# R7FA2L1AB register map
Vendor: Renesas Electronics Corporation; Series: RA2L1; File version: 1.60.00
CPU: CM23 r1p0, little endian, MPU, no FPU, VTOR, 2 interrupt priority bits, 32 interrupts
Registers are 8-bit, read-write, reset 0x0 unless marked. A register's access mark holds for its fields unless they carry their own. Offsets are from the block's base; [hi:lo] are bit positions; {n}, {i} and the like mark numbered series; 'fields as' and 'values as' point back to an identical list.

## PFS — Pmn Pin Function Control Register
Base 0x40040800
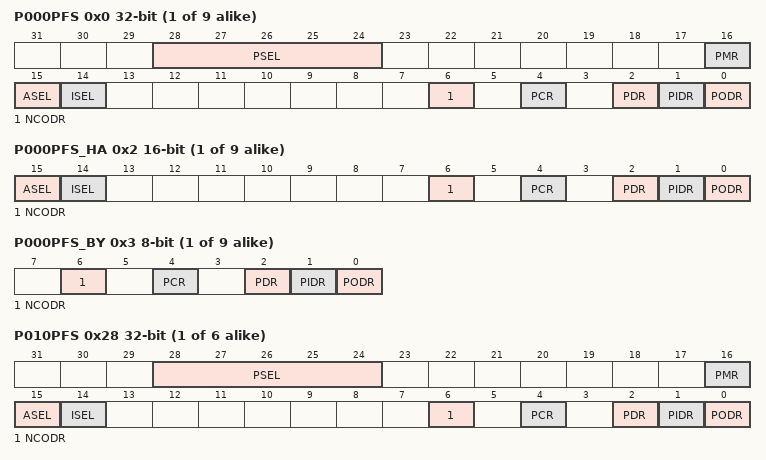
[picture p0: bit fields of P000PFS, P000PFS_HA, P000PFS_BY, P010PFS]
{0x0+4i} P00{i}PFS (i=0..8) 32-bit (reset mask 0xFFFFFFFD) — Port 00{i} Pin Function Select Register
  [28:24] PSEL — Peripheral Select
  [16] PMR — Port Mode Control
    0=Use as general I/O pin; 1=Use as I/O port for peripheral functions
  [15] ASEL — Analog Input Enable
    0=Do not use as analog pin; 1=Use as analog pin
  [14] ISEL — IRQ Input Enable
    0=Do not use as IRQn input pin; 1=Use as IRQn input pin
  [6] NCODR — N-Channel Open-Drain Control
    0=Output CMOS; 1=Output NMOS open-drain
  [4] PCR — Pull-up Control
    0=Disable input pull-up; 1=Enable input pull-up
  [2] PDR — Port Direction
    0=Input (functions as an input pin); 1=Output (functions as an output pin)
  [1] PIDR ro — Port State
    0=Low level; 1=High level
  [0] PODR — Port Output Data
    0=Output low; 1=Output high
{0x2+4i} P00{i}PFS_HA (i=0..8) 16-bit (reset mask 0xFFFD) (alternate view of P00{i}PFS) — Port 00{i} Pin Function Select Register
  [15] ASEL — Analog Input Enable
    0=Do not use as analog pin; 1=Use as analog pin
  [14] ISEL — IRQ Input Enable
    0=Do not use as IRQn input pin; 1=Use as IRQn input pin
  [6] NCODR — N-Channel Open-Drain Control
    0=Output CMOS; 1=Output NMOS open-drain
  [4] PCR — Pull-up Control
    0=Disable input pull-up; 1=Enable input pull-up
  [2] PDR — Port Direction
    values as P000PFS.PDR
  [1] PIDR ro — Port State
    0=Low level; 1=High level
  [0] PODR — Port Output Data
    0=Output low; 1=Output high
{0x3+4i} P00{i}PFS_BY (i=0..8) (reset mask 0xFD) (alternate view of P00{i}PFS) — Port 00{i} Pin Function Select Register
  [6] NCODR — N-Channel Open-Drain Control
    0=Output CMOS; 1=Output NMOS open-drain
  [4] PCR — Pull-up Control
    0=Disable input pull-up; 1=Enable input pull-up
  [2] PDR — Port Direction
    values as P000PFS.PDR
  [1] PIDR ro — Port State
    0=Low level; 1=High level
  [0] PODR — Port Output Data
    0=Output low; 1=Output high
{0x0+4i} P0{i}PFS (i=10..15) 32-bit (reset mask 0xFFFFFFFD) — Port 0{i} Pin Function Select Register
  fields as P000PFS
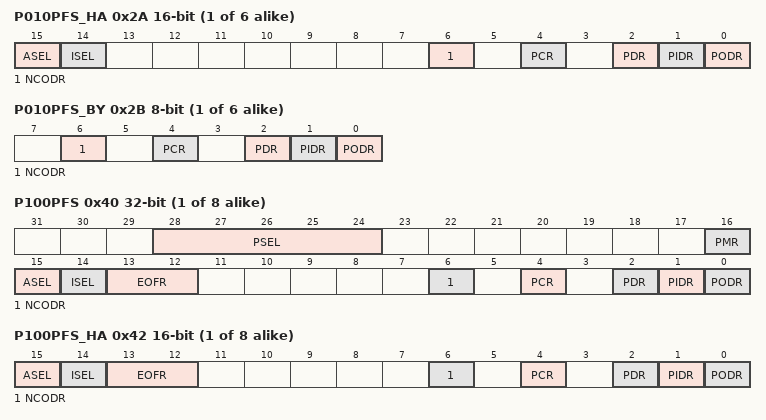
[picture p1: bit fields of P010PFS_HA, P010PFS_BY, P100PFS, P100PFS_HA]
{0x2+4i} P0{i}PFS_HA (i=10..15) 16-bit (reset mask 0xFFFD) (alternate view of P0{i}PFS) — Port 0{i} Pin Function Select Register
  fields as P000PFS_HA
{0x3+4i} P0{i}PFS_BY (i=10..15) (reset mask 0xFD) (alternate view of P0{i}PFS) — Port 0{i} Pin Function Select Register
  fields as P000PFS_BY
{0x40+4i} P10{i}PFS (i=0..7) 32-bit (reset mask 0xFFFFFFFD) — Port 10{i} Pin Function Select Register
  [28:24] PSEL — Peripheral Select
  [16] PMR — Port Mode Control
    values as P000PFS.PMR
  [15] ASEL — Analog Input Enable
    0=Do not use as analog pin; 1=Use as analog pin
  [14] ISEL — IRQ Input Enable
    0=Do not use as IRQn input pin; 1=Use as IRQn input pin
  [13:12] EOFR — Event on Falling/Event on Rising
    0=Don't care; 1=Detect rising edge; 2=Detect falling edge; 3=Detect both edges
  [6] NCODR — N-Channel Open-Drain Control
    0=Output CMOS; 1=Output NMOS open-drain
  [4] PCR — Pull-up Control
    0=Disable input pull-up; 1=Enable input pull-up
  [2] PDR — Port Direction
    values as P000PFS.PDR
  [1] PIDR ro — Port State
    0=Low level; 1=High level
  [0] PODR — Port Output Data
    0=Output low; 1=Output high
{0x42+4i} P10{i}PFS_HA (i=0..7) 16-bit (reset mask 0xFFFD) (alternate view of P10{i}PFS) — Port 10{i} Pin Function Select Register
  [15] ASEL — Analog Input Enable
    0=Do not use as analog pin; 1=Use as analog pin
  [14] ISEL — IRQ Input Enable
    0=Do not use as IRQn input pin; 1=Use as IRQn input pin
  [13:12] EOFR — Event on Falling/Event on Rising
    values as P100PFS.EOFR
  [6] NCODR — N-Channel Open-Drain Control
    0=Output CMOS; 1=Output NMOS open-drain
  [4] PCR — Pull-up Control
    0=Disable input pull-up; 1=Enable input pull-up
  [2] PDR — Port Direction
    values as P000PFS.PDR
  [1] PIDR ro — Port State
    0=Low level; 1=High level
  [0] PODR — Port Output Data
    0=Output low; 1=Output high
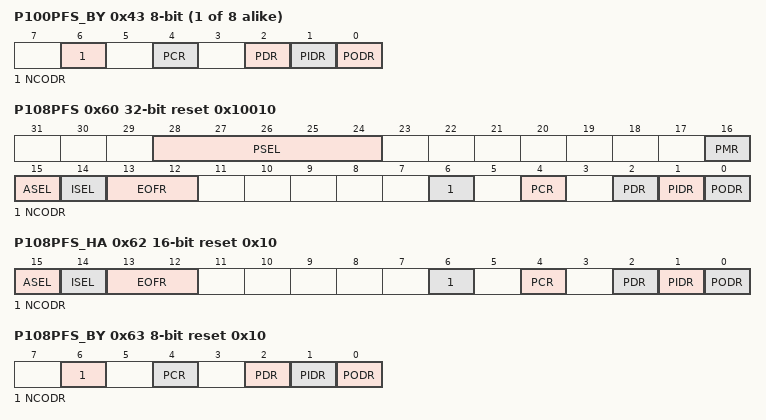
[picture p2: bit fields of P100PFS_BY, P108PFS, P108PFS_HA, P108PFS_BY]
{0x43+4i} P10{i}PFS_BY (i=0..7) (reset mask 0xFD) (alternate view of P10{i}PFS) — Port 10{i} Pin Function Select Register
  fields as P000PFS_BY
0x60 P108PFS 32-bit reset 0x10010 (reset mask 0xFFFFFFFD) — Port 108 Pin Function Select Register
  fields as P100PFS
0x62 P108PFS_HA 16-bit reset 0x10 (reset mask 0xFFFD) (alternate view of P108PFS) — Port 108 Pin Function Select Register
  fields as P100PFS_HA
0x63 P108PFS_BY reset 0x10 (reset mask 0xFD) (alternate view of P108PFS) — Port 108 Pin Function Select Register
  fields as P000PFS_BY
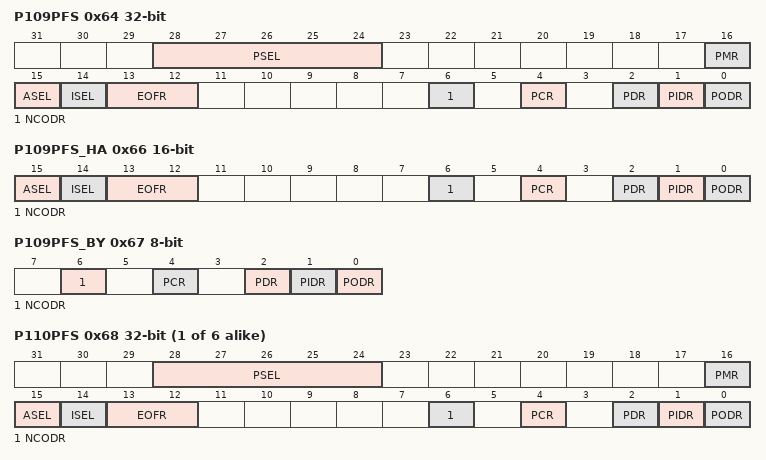
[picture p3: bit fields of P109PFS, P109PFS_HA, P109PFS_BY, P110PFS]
0x64 P109PFS 32-bit (reset mask 0xFFFFFFFD) — Port 109 Pin Function Select Register
  fields as P100PFS
0x66 P109PFS_HA 16-bit (reset mask 0xFFFD) (alternate view of P109PFS) — Port 109 Pin Function Select Register
  fields as P100PFS_HA
0x67 P109PFS_BY (reset mask 0xFD) (alternate view of P109PFS) — Port 109 Pin Function Select Register
  fields as P000PFS_BY
{0x40+4i} P1{i}PFS (i=10..15) 32-bit (reset mask 0xFFFFFFFD) — Port 1{i} Pin Function Select Register
  fields as P100PFS
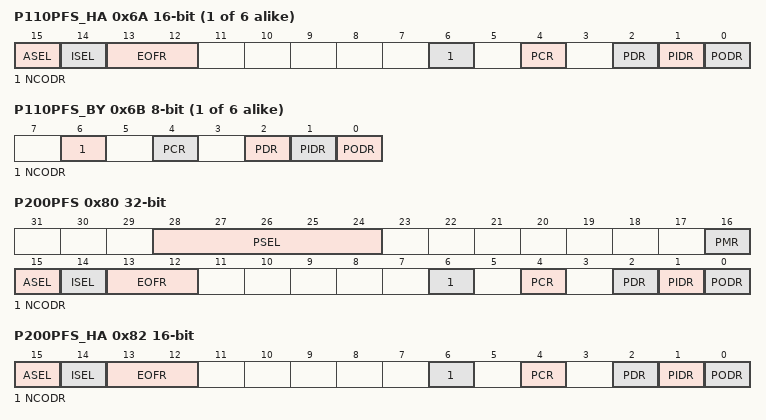
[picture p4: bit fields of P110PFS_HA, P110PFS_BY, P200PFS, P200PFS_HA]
{0x42+4i} P1{i}PFS_HA (i=10..15) 16-bit (reset mask 0xFFFD) (alternate view of P1{i}PFS) — Port 1{i} Pin Function Select Register
  fields as P100PFS_HA
{0x43+4i} P1{i}PFS_BY (i=10..15) (reset mask 0xFD) (alternate view of P1{i}PFS) — Port 1{i} Pin Function Select Register
  fields as P000PFS_BY
0x80 P200PFS 32-bit (reset mask 0xFFFFFFFD) — Port 200 Pin Function Select Register
  fields as P100PFS
0x82 P200PFS_HA 16-bit (reset mask 0xFFFD) (alternate view of P200PFS) — Port 200 Pin Function Select Register
  fields as P100PFS_HA
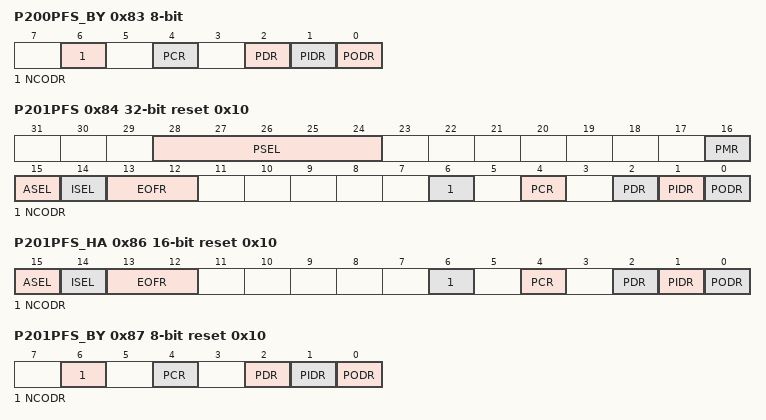
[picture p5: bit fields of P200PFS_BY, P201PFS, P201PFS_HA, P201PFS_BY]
0x83 P200PFS_BY (reset mask 0xFD) (alternate view of P200PFS) — Port 200 Pin Function Select Register
  fields as P000PFS_BY
0x84 P201PFS 32-bit reset 0x10 (reset mask 0xFFFFFFFD) — Port 201 Pin Function Select Register
  fields as P100PFS
0x86 P201PFS_HA 16-bit reset 0x10 (reset mask 0xFFFD) (alternate view of P201PFS) — Port 201 Pin Function Select Register
  fields as P100PFS_HA
0x87 P201PFS_BY reset 0x10 (reset mask 0xFD) (alternate view of P201PFS) — Port 201 Pin Function Select Register
  fields as P000PFS_BY
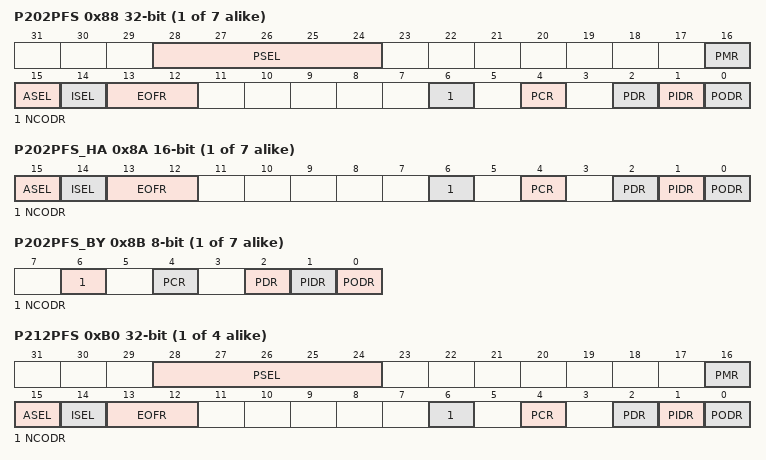
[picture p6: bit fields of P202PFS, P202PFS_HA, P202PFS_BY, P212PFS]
{0x80+4i} P20{i}PFS (i=2..8) 32-bit (reset mask 0xFFFFFFFD) — Port 20{i} Pin Function Select Register
  fields as P100PFS
{0x82+4i} P20{i}PFS_HA (i=2..8) 16-bit (reset mask 0xFFFD) (alternate view of P20{i}PFS) — Port 20{i} Pin Function Select Register
  fields as P100PFS_HA
{0x83+4i} P20{i}PFS_BY (i=2..8) (reset mask 0xFD) (alternate view of P20{i}PFS) — Port 20{i} Pin Function Select Register
  fields as P000PFS_BY
{0x80+4i} P2{i}PFS (i=12..15) 32-bit (reset mask 0xFFFFFFFD) — Port 2{i} Pin Function Select Register
  fields as P100PFS
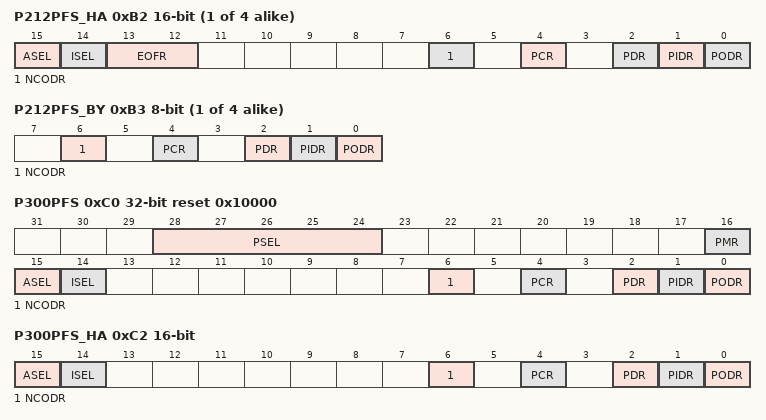
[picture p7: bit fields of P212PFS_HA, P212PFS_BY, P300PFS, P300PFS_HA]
{0x82+4i} P2{i}PFS_HA (i=12..15) 16-bit (reset mask 0xFFFD) (alternate view of P2{i}PFS) — Port 2{i} Pin Function Select Register
  fields as P100PFS_HA
{0x83+4i} P2{i}PFS_BY (i=12..15) (reset mask 0xFD) (alternate view of P2{i}PFS) — Port 2{i} Pin Function Select Register
  fields as P000PFS_BY
0xC0 P300PFS 32-bit reset 0x10000 (reset mask 0xFFFFFFFD) — Port 300 Pin Function Select Register
  fields as P000PFS
0xC2 P300PFS_HA 16-bit (reset mask 0xFFFD) (alternate view of P300PFS) — Port 300 Pin Function Select Register
  fields as P000PFS_HA
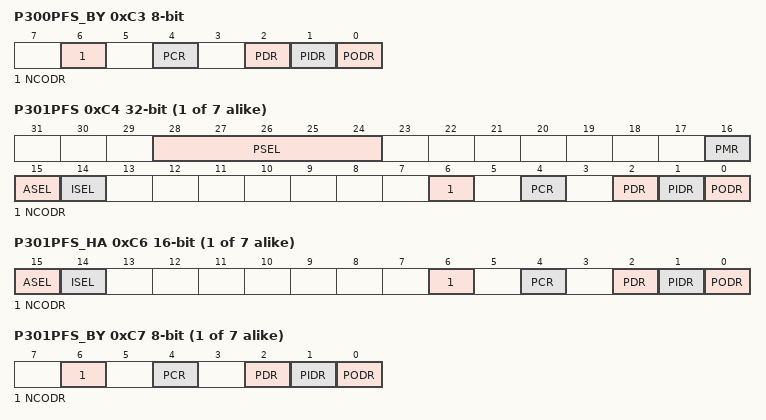
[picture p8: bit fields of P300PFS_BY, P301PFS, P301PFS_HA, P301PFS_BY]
0xC3 P300PFS_BY (reset mask 0xFD) (alternate view of P300PFS) — Port 300 Pin Function Select Register
  fields as P000PFS_BY
{0xC0+4i} P30{i}PFS (i=1..7) 32-bit (reset mask 0xFFFFFFFD) — Port 30{i} Pin Function Select Register
  fields as P000PFS
{0xC2+4i} P30{i}PFS_HA (i=1..7) 16-bit (reset mask 0xFFFD) (alternate view of P30{i}PFS) — Port 30{i} Pin Function Select Register
  fields as P000PFS_HA
{0xC3+4i} P30{i}PFS_BY (i=1..7) (reset mask 0xFD) (alternate view of P30{i}PFS) — Port 30{i} Pin Function Select Register
  fields as P000PFS_BY
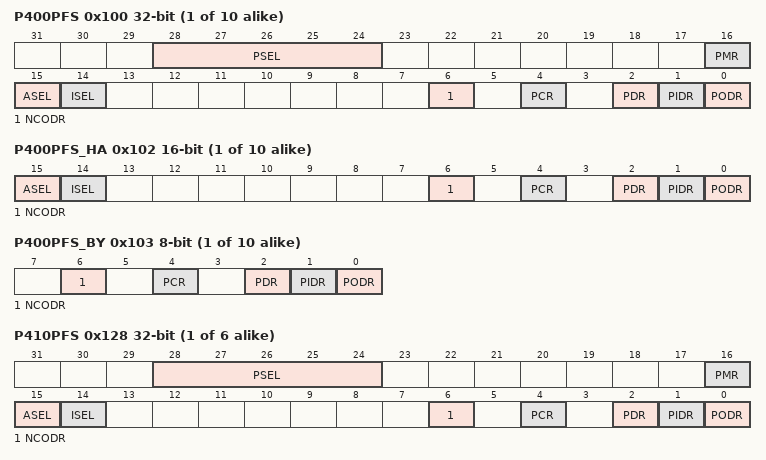
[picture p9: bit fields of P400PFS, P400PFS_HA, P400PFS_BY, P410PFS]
{0x100+4i} P40{i}PFS (i=0..9) 32-bit (reset mask 0xFFFFFFFD) — Port 40{i} Pin Function Select Register
  fields as P000PFS
{0x102+4i} P40{i}PFS_HA (i=0..9) 16-bit (reset mask 0xFFFD) (alternate view of P40{i}PFS) — Port 40{i} Pin Function Select Register
  fields as P000PFS_HA
{0x103+4i} P40{i}PFS_BY (i=0..9) (reset mask 0xFD) (alternate view of P40{i}PFS) — Port 40{i} Pin Function Select Register
  fields as P000PFS_BY
{0x100+4i} P4{i}PFS (i=10..15) 32-bit (reset mask 0xFFFFFFFD) — Port 4{i} Pin Function Select Register
  fields as P000PFS
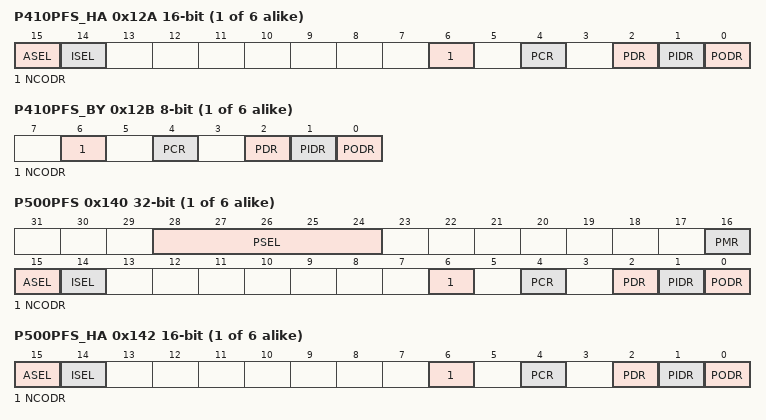
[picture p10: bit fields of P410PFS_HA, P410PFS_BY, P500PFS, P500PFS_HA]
{0x102+4i} P4{i}PFS_HA (i=10..15) 16-bit (reset mask 0xFFFD) (alternate view of P4{i}PFS) — Port 4{i} Pin Function Select Register
  fields as P000PFS_HA
{0x103+4i} P4{i}PFS_BY (i=10..15) (reset mask 0xFD) (alternate view of P4{i}PFS) — Port 4{i} Pin Function Select Register
  fields as P000PFS_BY
{0x140+4i} P50{i}PFS (i=0..5) 32-bit (reset mask 0xFFFFFFFD) — Port 50{i} Pin Function Select Register
  fields as P000PFS
{0x142+4i} P50{i}PFS_HA (i=0..5) 16-bit (reset mask 0xFFFD) (alternate view of P50{i}PFS) — Port 50{i} Pin Function Select Register
  fields as P000PFS_HA
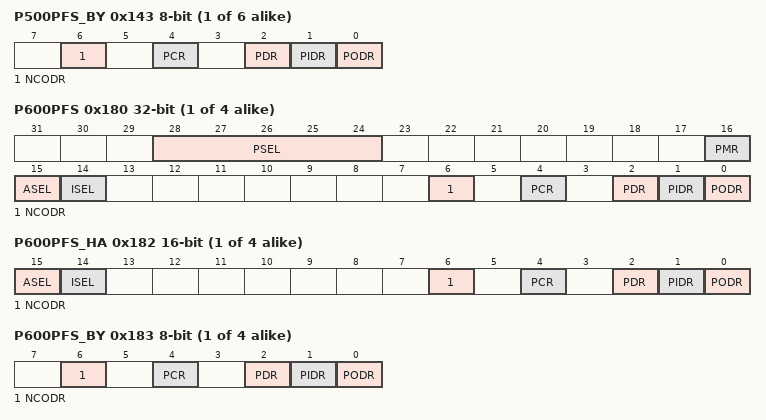
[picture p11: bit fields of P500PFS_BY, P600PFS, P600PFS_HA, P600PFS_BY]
{0x143+4i} P50{i}PFS_BY (i=0..5) (reset mask 0xFD) (alternate view of P50{i}PFS) — Port 50{i} Pin Function Select Register
  fields as P000PFS_BY
{0x180+4i} P60{i}PFS (i=0..3) 32-bit (reset mask 0xFFFFFFFD) — Port 60{i} Pin Function Select Register
  fields as P000PFS
{0x182+4i} P60{i}PFS_HA (i=0..3) 16-bit (reset mask 0xFFFD) (alternate view of P60{i}PFS) — Port 60{i} Pin Function Select Register
  fields as P000PFS_HA
{0x183+4i} P60{i}PFS_BY (i=0..3) (reset mask 0xFD) (alternate view of P60{i}PFS) — Port 60{i} Pin Function Select Register
  fields as P000PFS_BY
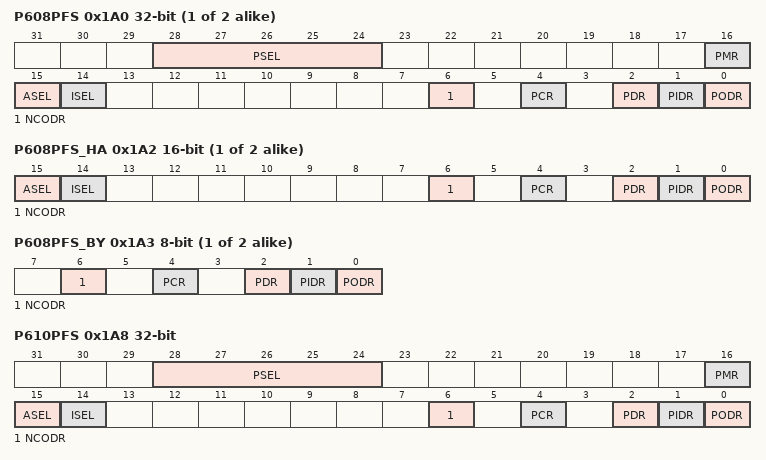
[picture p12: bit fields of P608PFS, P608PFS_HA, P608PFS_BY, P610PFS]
{0x180+4i} P60{i}PFS (i=8..9) 32-bit (reset mask 0xFFFFFFFD) — Port 60{i} Pin Function Select Register
  fields as P000PFS
{0x182+4i} P60{i}PFS_HA (i=8..9) 16-bit (reset mask 0xFFFD) (alternate view of P60{i}PFS) — Port 60{i} Pin Function Select Register
  fields as P000PFS_HA
{0x183+4i} P60{i}PFS_BY (i=8..9) (reset mask 0xFD) (alternate view of P60{i}PFS) — Port 60{i} Pin Function Select Register
  fields as P000PFS_BY
0x1A8 P610PFS 32-bit (reset mask 0xFFFFFFFD) — Port 610 Pin Function Select Register
  fields as P000PFS
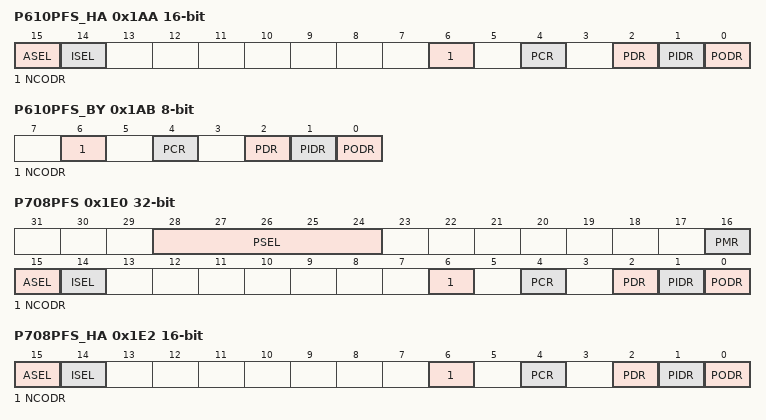
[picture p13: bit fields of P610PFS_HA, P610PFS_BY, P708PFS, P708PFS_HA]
0x1AA P610PFS_HA 16-bit (reset mask 0xFFFD) (alternate view of P610PFS) — Port 610 Pin Function Select Register
  fields as P000PFS_HA
0x1AB P610PFS_BY (reset mask 0xFD) (alternate view of P610PFS) — Port 610 Pin Function Select Register
  fields as P000PFS_BY
0x1E0 P708PFS 32-bit (reset mask 0xFFFFFFFD) — Port 708 Pin Function Select Register
  fields as P000PFS
0x1E2 P708PFS_HA 16-bit (reset mask 0xFFFD) (alternate view of P708PFS) — Port 708 Pin Function Select Register
  fields as P000PFS_HA
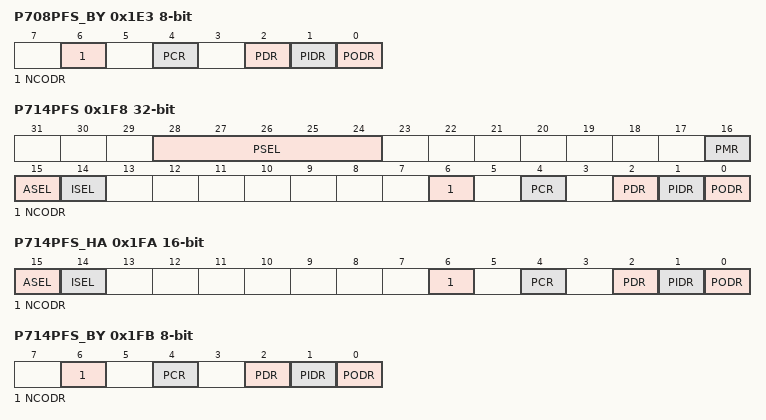
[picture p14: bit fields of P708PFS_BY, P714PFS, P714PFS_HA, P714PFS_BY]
0x1E3 P708PFS_BY (reset mask 0xFD) (alternate view of P708PFS) — Port 708 Pin Function Select Register
  fields as P000PFS_BY
0x1F8 P714PFS 32-bit (reset mask 0xFFFFFFFD) — Port 714 Pin Function Select Register
  fields as P000PFS
0x1FA P714PFS_HA 16-bit (reset mask 0xFFFD) (alternate view of P714PFS) — Port 714 Pin Function Select Register
  fields as P000PFS_HA
0x1FB P714PFS_BY (reset mask 0xFD) (alternate view of P714PFS) — Port 714 Pin Function Select Register
  fields as P000PFS_BY
{0x200+4i} P80{i}PFS (i=8..9) 32-bit (reset mask 0xFFFFFFFD) — Port 80{i} Pin Function Select Register
  fields as P000PFS
{0x202+4i} P80{i}PFS_HA (i=8..9) 16-bit (reset mask 0xFFFD) (alternate view of P80{i}PFS) — Port 80{i} Pin Function Select Register
  fields as P000PFS_HA
{0x203+4i} P80{i}PFS_BY (i=8..9) (reset mask 0xFD) (alternate view of P80{i}PFS) — Port 80{i} Pin Function Select Register
  fields as P000PFS_BY
0x503 PWPR reset 0x80 — Write-Protect Register
  [7] B0WI — PFSWE Bit Write Disable
    0=Writing to the PFSWE bit is enabled; 1=Writing to the PFSWE bit is disabled
  [6] PFSWE — PmnPFS Register Write Enable
    0=Writing to the PmnPFS register is disabled; 1=Writing to the PmnPFS register is enabled
0x50F PRWCNTR reset 0x1 — Port Read Wait Control Register
  [1:0] WAIT — Wait Cycle Control
    0=Setting prohibited; 1=Insert a 1-cycle wait; 2=Insert a 2-cycle wait; 3=Insert a 3-cycle wait
